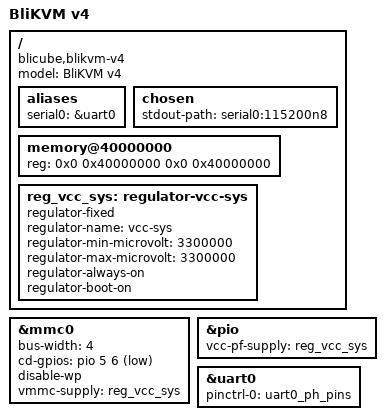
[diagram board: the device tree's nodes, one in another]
// SPDX-License-Identifier: (GPL-2.0+ OR MIT)
/* Bootloader candidate: describe only verified UART0 and removable MMC0. */
/dts-v1/;

#include "sun50i-h616.dtsi"
#include <dt-bindings/gpio/gpio.h>

/ {
	model = "BliKVM v4";
	compatible = "blicube,blikvm-v4", "allwinner,sun50i-h616";

	aliases {
		serial0 = &uart0;
	};

	chosen {
		stdout-path = "serial0:115200n8";
	};

	memory@40000000 {
		device_type = "memory";
		reg = <0x0 0x40000000 0x0 0x40000000>;
	};

	reg_vcc_sys: regulator-vcc-sys {
		compatible = "regulator-fixed";
		regulator-name = "vcc-sys";
		regulator-min-microvolt = <3300000>;
		regulator-max-microvolt = <3300000>;
		regulator-always-on;
		regulator-boot-on;
	};
};

&mmc0 {
	bus-width = <4>;
	cd-gpios = <&pio 5 6 GPIO_ACTIVE_LOW>;
	disable-wp;
	vmmc-supply = <&reg_vcc_sys>;
	status = "okay";
};

&pio {
	vcc-pf-supply = <&reg_vcc_sys>;
};

&uart0 {
	pinctrl-names = "default";
	pinctrl-0 = <&uart0_ph_pins>;
	status = "okay";
};
